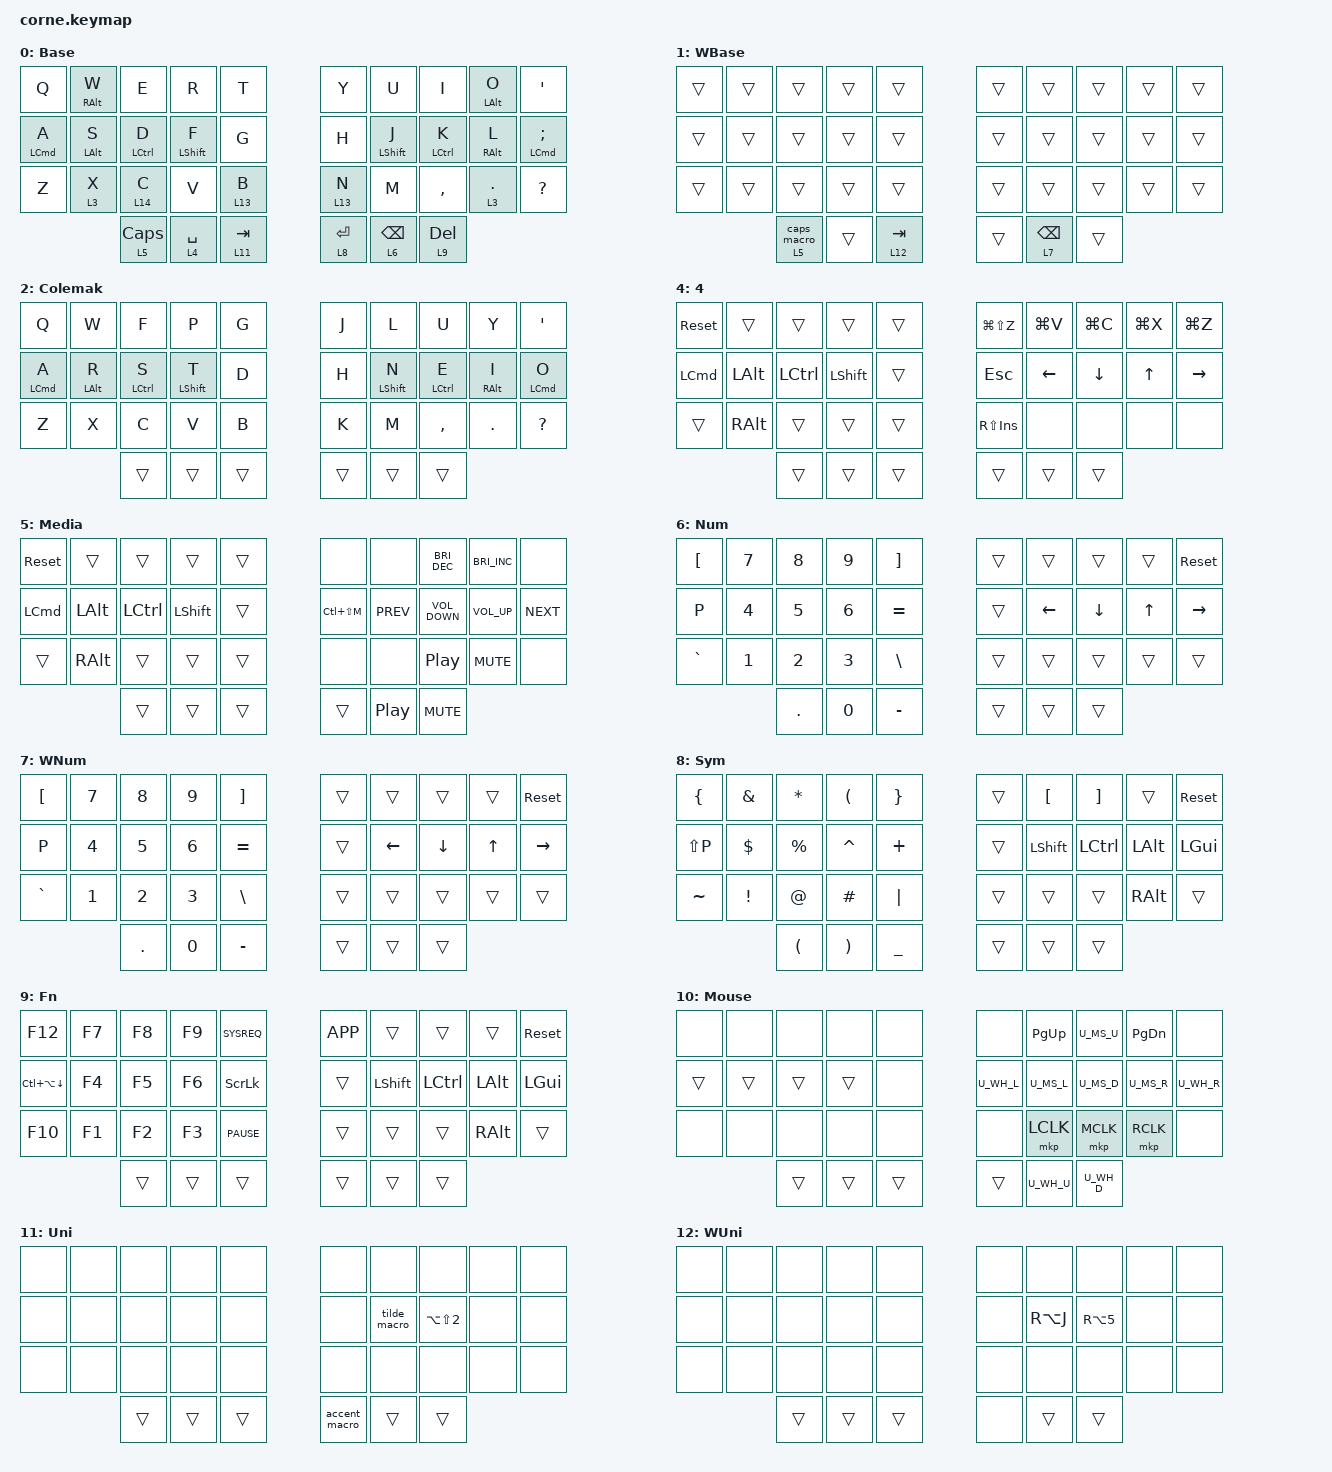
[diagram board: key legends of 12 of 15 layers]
/*
 * Copyright (c) 2020 The ZMK Contributors
 *
 * SPDX-License-Identifier: MIT
 */

#include <behaviors.dtsi>
#include <dt-bindings/zmk/bt.h>
#include <dt-bindings/zmk/keys.h>
#include <dt-bindings/zmk/pointing.h>
#include "mouse.dtsi"

//#include "zmk-helpers/helper.h"
//#include "zmk-helpers/key-labels/36.h"

#define COMBO_IDLE_MS 280
#define MOUSE 10

// Smart-mouse, requires tri-state module.
/*
ZMK_TRI_STATE(
    smart_mouse,
    bindings = <&tog MOUSE>, <&none>, <&tog MOUSE>;
    ignored-key-positions =
        <RT0 RT1 RT2 RT3 RM0 RM1 RM2 RM3 RM4 RB1 RB2 RB3 RH1 RH2>;
    ignored-layers = <MOUSE>;
)
*/

&caps_word { continue-list = <UNDERSCORE BACKSPACE DELETE SEMICOLON>; };

/ {
    chosen { zmk,matrix_transform = &five_column_transform; };
};

/ {
    behaviors {
        smart_mouse: smart_mouse {
            compatible = "zmk,behavior-tri-state";
            label = "SMART_MOUSE";
            #binding-cells = <0>;

            /* first press, second press, interruption */

            bindings = <&tog MOUSE>, <&none>, <&tog MOUSE>;

            /* optional: start simple, add these later if desired */

            ignored-key-positions = <5 6 7 8 9 10 11 12 13 14 15 16 17 18 19 25 26 27 28 29 33 34 35>;
            ignored-layers = <MOUSE>;
        };

        hold_layer: hold_layer {
            compatible = "zmk,behavior-hold-tap";
            label = "HOLD_LAYER";
            bindings = <&mo>, <&kp>;

            #binding-cells = <2>;
            tapping-term-ms = <175>;
            flavor = "tap-preferred";
            quick-tap-ms = <250>;
        };

        hold_tap: hold_tap {
            compatible = "zmk,behavior-hold-tap";
            label = "HOLD_TAP";
            bindings = <&kp>, <&kp>;

            #binding-cells = <2>;
            tapping-term-ms = <250>;
            flavor = "tap-preferred";
        };

        hmr: hmr {
            compatible = "zmk,behavior-hold-tap";
            label = "HMR";
            bindings = <&kp>, <&kp>;

            #binding-cells = <2>;
            tapping-term-ms = <230>;
            quick-tap-ms = <175>;
            require-prior-idle-ms = <150>;
            flavor = "balanced";
            hold-trigger-key-positions = <0 1 2 3 4 10 11 12 13 14 20 21 22 23 24 30 31 32 33 34 35>;
            hold-trigger-on-release;
        };

        hml: hml {
            compatible = "zmk,behavior-hold-tap";
            label = "HML";
            bindings = <&kp>, <&kp>;

            #binding-cells = <2>;
            tapping-term-ms = <230>;
            quick-tap-ms = <175>;
            require-prior-idle-ms = <150>;
            flavor = "balanced";
            hold-trigger-on-release;
            hold-trigger-key-positions = <5 6 7 8 9 15 16 17 18 19 25 26 27 28 29 33 34 35 30 31 32>;
        };

        lpar_lt: lpar_lt {
            compatible = "zmk,behavior-mod-morph";
            label = "LPAR_LT";
            bindings = <&kp LPAR>, <&kp LT>;

            #binding-cells = <0>;
            mods = <(MOD_LSFT)>;
        };

        hmr_parens_lt: hmr_parens_lt {
            compatible = "zmk,behavior-hold-tap";
            label = "HMR_PARENS_LT";
            bindings = <&kp>, <&parens_lt>;

            #binding-cells = <2>;
            tapping-term-ms = <280>;
            quick-tap-ms = <175>;
            require-prior-idle-ms = <150>;
            flavor = "balanced";
            hold-trigger-key-positions = <0 1 2 3 4 10 11 12 13 14 20 21 22 23 24 30 31 32 33 34 35>;
            hold-trigger-on-release;
        };

        rpar_gt: rpar_gt {
            compatible = "zmk,behavior-mod-morph";
            label = "RPAR_GT";
            bindings = <&kp RPAR>, <&kp GT>;

            #binding-cells = <0>;
            mods = <(MOD_LSFT)>;
        };

        hmr_curlybkts_gt: hmr_curlybkts_gt {
            compatible = "zmk,behavior-hold-tap";
            label = "HMR_CURLYBKTS_GT";
            bindings = <&kp>, <&curlybkts_gt>;

            #binding-cells = <2>;
            tapping-term-ms = <280>;
            quick-tap-ms = <175>;
            require-prior-idle-ms = <150>;
            flavor = "balanced";
            hold-trigger-key-positions = <0 1 2 3 4 10 11 12 13 14 20 21 22 23 24 30 31 32 33 34 35>;
            hold-trigger-on-release;
        };

        lbkt_lbrc: lbkt_lbrc {
            compatible = "zmk,behavior-mod-morph";
            label = "LBKT_LBRC";
            bindings = <&kp LBKT>, <&kp LBRC>;

            #binding-cells = <0>;
            mods = <(MOD_LSFT)>;
        };

        rbkt_rbrc: rbkt_rbrc {
            compatible = "zmk,behavior-mod-morph";
            label = "RBKT_RBRC";
            bindings = <&kp RBKT>, <&kp RBRC>;

            #binding-cells = <0>;
            mods = <(MOD_LSFT)>;
        };

        hml_repeat: hml_repeat {
            compatible = "zmk,behavior-hold-tap";
            label = "HML_REPEAT";
            bindings = <&kp>, <&key_repeat>;

            #binding-cells = <2>;
            tapping-term-ms = <280>;
            quick-tap-ms = <175>;
            require-prior-idle-ms = <150>;
            flavor = "balanced";
            hold-trigger-on-release;
            hold-trigger-key-positions = <5 6 7 8 9 15 16 17 18 19 25 26 27 28 29 33 34 35 32 31 30>;
        };

        holdLayer_Caps: holdLayer_Caps {
            compatible = "zmk,behavior-hold-tap";
            label = "HOLDLAYER_CAPS";
            bindings = <&mo>, <&caps_macro>;

            #binding-cells = <2>;
            tapping-term-ms = <175>;
            quick-tap-ms = <250>;
            flavor = "tap-preferred";
        };

        parens_lt: parens_lt {
            compatible = "zmk,behavior-mod-morph";
            label = "PARENS_LT";
            bindings = <&parens_macro>, <&kp LESS_THAN>;

            #binding-cells = <0>;
            mods = <(MOD_LSFT)>;
        };

        curlybkts_gt: curlybkts_gt {
            compatible = "zmk,behavior-mod-morph";
            label = "CURLYBKTS_GT";
            bindings = <&curlybkts_macro>, <&kp GT>;

            #binding-cells = <0>;
            mods = <(MOD_LSFT)>;
        };

        sqbkts_none: sqbkts_none {
            compatible = "zmk,behavior-mod-morph";
            label = "SQBKTS_NONE";
            bindings = <&sqbkts_macro>, <&none>;

            #binding-cells = <0>;
            mods = <(MOD_LSFT)>;
        };

        hmr_shft: hmr_shft {
            compatible = "zmk,behavior-hold-tap";
            label = "HMR_SHFT";
            bindings = <&kp>, <&kp>;

            #binding-cells = <2>;
            tapping-term-ms = <280>;
            quick-tap-ms = <175>;
            require-prior-idle-ms = <150>;
            flavor = "balanced";
            hold-trigger-on-release;
            hold-trigger-key-positions = <0 1 3 4 10 11 20 21 22 23 24 30 31 32 0 1 2 3 4 10 11 20 21 22 23 24 30 31 32 12 13 14>;
        };

        hml_shft: hml_shft {
            compatible = "zmk,behavior-hold-tap";
            label = "HML_SHFT";
            bindings = <&kp>, <&kp>;

            #binding-cells = <2>;
            tapping-term-ms = <280>;
            quick-tap-ms = <175>;
            require-prior-idle-ms = <150>;
            flavor = "balanced";
            hold-trigger-on-release;
            hold-trigger-key-positions = <5 6 7 8 9 15 18 19 25 26 27 28 29 33 34 35 16 17>;
        };

        sl_hold_tap: sl_hold_tap {
            compatible = "zmk,behavior-hold-tap";
            label = "SL_HOLD_TAP";
            bindings = <&sl>, <&kp>;

            #binding-cells = <2>;
            tapping-term-ms = <200>;
            flavor = "tap-preferred";
        };

        quote_dblquote: quote_dblquote {
            compatible = "zmk,behavior-mod-morph";
            label = "QUOTE_DBLQUOTE";
            bindings = <&dblquote_macro>, <&quote_macro>;

            #binding-cells = <0>;
            mods = <(MOD_LSFT)>;
        };

        dbckwrd_dbckline: dbckwrd_dbckline {
            compatible = "zmk,behavior-mod-morph";
            label = "DBCKWRD_DBCKLINE";
            bindings = <&kp LA(BACKSPACE)>, <&kp RG(BACKSPACE)>;

            #binding-cells = <0>;
            mods = <(MOD_LSFT)>;
        };

        win_dbckwrd_dbckline: win_dbckwrd_dbckline {
            compatible = "zmk,behavior-mod-morph";
            label = "WIN_DBCKWRD_DBCKLINE";
            bindings = <&kp LC(BACKSPACE)>, <&win_dbckline_macro>;

            #binding-cells = <0>;
            mods = <(MOD_LSFT)>;
        };

        dfwdwrd_dfwdline: dfwdwrd_dfwdline {
            compatible = "zmk,behavior-mod-morph";
            label = "DFWDWRD_DFWDLINE";
            bindings = <&kp LA(DEL)>, <&dfwdline_macro>;

            #binding-cells = <0>;
            mods = <(MOD_LSFT)>;
        };

        win_dfwdwrd_dfwdline: win_dfwdwrd_dfwdline {
            compatible = "zmk,behavior-mod-morph";
            label = "WIN_DFWDWRD_DFWDLINE";
            bindings = <&kp LC(DEL)>, <&win_dfwdline_macro>;

            #binding-cells = <0>;
            mods = <(MOD_LSFT)>;
        };

        sqk: sqk {
            compatible = "zmk,behavior-sticky-key";
            label = "SQK";
            bindings = <&kp>;
            #binding-cells = <1>;
            quick-release;
            ignore-modifiers;
            release-after-ms = <60000>;
        };

        td_tmux: tap_dance_tmux {
            compatible = "zmk,behavior-tap-dance";
            label = "TAP_DANCE_TMUX";
            #binding-cells = <0>;
            tapping-term-ms = <200>;
            bindings = <&kp LC(A)>, <&kp LC(G)>;
        };

        fn_ptt: fn_ptt {
            compatible = "zmk,behavior-hold-tap";
            label = "FN_PTT";
            bindings = <&kp>, <&kp>;

            #binding-cells = <2>;
            tapping-term-ms = <170>;
            flavor = "tap-preferred";
        };
    };

    combos {
        compatible = "zmk,combos";

        mac_layer {
            bindings = <&to 0>;
            key-positions = <23 26>;
            layers = <13 2 3 4 5 6 8 9 10 1 7>;
        };

        lower_layer {
            bindings = <&to 13>;
            key-positions = <23 26>;
            layers = <0>;
            timeout-ms = <25>;
        };

        num_layer {
            bindings = <&to 6>;
            key-positions = <3 4>;
            layers = <0>;
        };

        caps_word {
            bindings = <&caps_word>;
            key-positions = <14 15>;
        };

        lock_screen {
            bindings = <&kp LC(LG(Q))>;
            key-positions = <0 9>;
        };

        cut {
            bindings = <&kp LG(X)>;
            key-positions = <23 21>;
            layers = <0 6>;
        };

        copy {
            bindings = <&kp LG(C)>;
            key-positions = <21 22>;
            layers = <0 6>;
        };

        paste {
            bindings = <&kp LG(V)>;
            key-positions = <22 23>;
            layers = <0 6>;
        };

        parens_lt {
            bindings = <&hmr_parens_lt RS(LCTRL) 0>;
            key-positions = <16 17>;
            require-prior-idle-ms = <COMBO_IDLE_MS>;
        };

        curlybkts_gt {
            bindings = <&hmr_curlybkts_gt RS(LALT) 0>;
            key-positions = <17 18>;
            require-prior-idle-ms = <COMBO_IDLE_MS>;
        };

        sqbkts_none {
            bindings = <&sqbkts_none>;
            key-positions = <26 27>;
            require-prior-idle-ms = <COMBO_IDLE_MS>;
        };

        none {
            bindings = <&none>;
            key-positions = <27 28>;
        };

        caret {
            bindings = <&kp CARET>;
            key-positions = <5 15>;
        };

        plus {
            bindings = <&kp PLUS>;
            key-positions = <6 16>;
        };

        star {
            bindings = <&kp STAR>;
            key-positions = <7 17>;
        };

        amps {
            bindings = <&kp AMPS>;
            key-positions = <8 18>;
        };

        under {
            bindings = <&kp UNDER>;
            key-positions = <15 25>;
        };

        minus {
            bindings = <&kp MINUS>;
            key-positions = <26 16>;
        };

        fslh {
            bindings = <&kp FSLH>;
            key-positions = <17 27>;
        };

        pipe {
            bindings = <&kp PIPE>;
            key-positions = <18 28>;
        };

        backspace {
            bindings = <&kp BACKSPACE>;
            key-positions = <1 2>;
        };

        enter {
            bindings = <&kp ENTER>;
            key-positions = <2 3>;
        };

        tab {
            bindings = <&hml LS(LALT) TAB>;
            key-positions = <11 12>;
        };

        repeat {
            bindings = <&hml_repeat LS(LCTRL) 0>;
            key-positions = <12 13>;
        };

        space {
            bindings = <&kp SPACE>;
            key-positions = <14 13>;
        };

        cut_win {
            bindings = <&kp LC(X)>;
            key-positions = <23 21>;
            layers = <1 7>;
        };

        copy_win {
            bindings = <&kp LC(INS)>;
            key-positions = <21 22>;
            layers = <1 7>;
        };

        paste_win {
            bindings = <&kp LS(INS)>;
            key-positions = <23 22>;
            layers = <1 7>;
        };

        at {
            bindings = <&kp AT>;
            key-positions = <1 11>;
        };

        hash {
            bindings = <&kp HASH>;
            key-positions = <2 12>;
        };

        dllr {
            bindings = <&kp DLLR>;
            key-positions = <3 13>;
        };

        prcnt {
            bindings = <&kp PRCNT>;
            key-positions = <4 14>;
        };

        grave {
            bindings = <&kp GRAVE>;
            key-positions = <11 21>;
        };

        bslh {
            bindings = <&kp BSLH>;
            key-positions = <12 22>;
        };

        equal {
            bindings = <&kp EQUAL>;
            key-positions = <13 23>;
        };

        tilde {
            bindings = <&kp TILDE>;
            key-positions = <14 24>;
        };

        tmux_leading {
            bindings = <&td_tmux>;
            key-positions = <34 31>;
        };

        fn_ptt {
            bindings = <&fn_ptt F16 LC(F16)>;
            key-positions = <31 32>;
        };

        R_in_pipe {
            bindings = <&R_in_pipe>;
            key-positions = <16 18>;
            require-prior-idle-ms = <COMBO_IDLE_MS>;
        };

        R_pipe {
            bindings = <&R_pipe>;
            key-positions = <3 16>;
            require-prior-idle-ms = <COMBO_IDLE_MS>;
        };

        mouse {
            bindings = <&smart_mouse>;
            key-positions = <5 6>;
        };

        caps {
            bindings = <&kp ESC>;
            key-positions = <15 16>;
            layers = <0 2>;
        };

        win_layer {
            bindings = <&to 1>;
            key-positions = <24 25>;
            layers = <13 2 3 4 5 8 9 10 0 7 6>;
        };

        caps_win {
            bindings = <&kp ESC>;
            key-positions = <15 16>;
            layers = <1>;
        };

        start_line {
            bindings = <&kp LG(LEFT)>;
            key-positions = <25 26>;
            layers = <0>;
        };

        end_line {
            bindings = <&kp LG(RIGHT)>;
            key-positions = <29 28>;
            layers = <0>;
        };

        start_line_win {
            bindings = <&kp HOME>;
            key-positions = <25 26>;
            layers = <1>;
        };

        end_line_win {
            bindings = <&kp END>;
            key-positions = <29 28>;
            layers = <1>;
        };

        mac_scrnsht {
            bindings = <&kp LG(LC(LS(NUMBER_4)))>;
            key-positions = <20 21>;
            layers = <0>;
        };

        win_scrnsht {
            bindings = <&kp PSCRN>;
            key-positions = <20 21>;
            layers = <1>;
        };

        dbck_wrd {
            bindings = <&kp LA(BACKSPACE)>;
            key-positions = <>;
            layers = <0>;
        };

        dnxt_wrd {
            bindings = <&kp LA(DEL)>;
            key-positions = <>;
            layers = <0>;
        };

        win_dbck_wrd {
            bindings = <&kp LC(BACKSPACE)>;
            key-positions = <>;
            layers = <1>;
        };

        win_dnxt_wrd {
            bindings = <&kp LC(DEL)>;
            key-positions = <>;
            layers = <1>;
        };

        navbck_wrd {
            bindings = <&kp LA(LEFT)>;
            key-positions = <6 7>;
            layers = <0>;
        };

        navnxt_wrd {
            bindings = <&kp LA(RIGHT)>;
            key-positions = <7 8>;
            layers = <0>;
        };

        win_navbck_wrd {
            bindings = <&kp LC(LEFT)>;
            key-positions = <6 7>;
            layers = <1>;
        };

        win_navnxt_wrd {
            bindings = <&kp LC(RIGHT)>;
            key-positions = <7 8>;
            layers = <1>;
        };

        clipboard {
            bindings = <&kp RA(RG(C))>;
            key-positions = <10 11>;
            layers = <0>;
            require-prior-idle-ms = <COMBO_IDLE_MS>;
        };

        win_clipboard {
            bindings = <&kp LC(GRAVE)>;
            key-positions = <10 11>;
            layers = <1>;
            require-prior-idle-ms = <COMBO_IDLE_MS>;
        };

        wnum_layer {
            bindings = <&to 7>;
            key-positions = <3 4>;
            layers = <1>;
        };

        quote_dblquote {
            bindings = <&quote_dblquote>;
            key-positions = <9 19>;
            require-prior-idle-ms = <COMBO_IDLE_MS>;
        };

        dbckwrd_dbckline {
            bindings = <&dbckwrd_dbckline>;
            key-positions = <30 31>;
            layers = <0>;
        };

        win_dbckwrd_dbckline {
            bindings = <&win_dbckwrd_dbckline>;
            key-positions = <30 31>;
            layers = <1>;
        };

        dfwdwrd_dfwdline {
            bindings = <&dfwdwrd_dfwdline>;
            key-positions = <35 34>;
            layers = <0>;
        };

        win_dfwdwrd_dfwdline {
            bindings = <&win_dfwdwrd_dfwdline>;
            key-positions = <35 34>;
            layers = <1>;
        };

        shift-enter {
            bindings = <&kp RS(ENTER)>;
            key-positions = <16 33>;
        };

        sticky-shift {
            bindings = <&sqk LEFT_SHIFT>;
            key-positions = <32 33>;
        };

        win_context_menu {
            bindings = <&kp K_CONTEXT_MENU>;
            key-positions = <0 1>;
        };
    };

    macros {
        R_in_pipe: R_in_pipe {
            compatible = "zmk,behavior-macro";
            #binding-cells = <0>;
            bindings = <&none &kp PRCNT &kp L &kp J &kp PRCNT>;
            label = "R_IN_PIPE";
        };

        R_pipe: R_pipe {
            compatible = "zmk,behavior-macro";
            #binding-cells = <0>;
            bindings = <&none &kp PRCNT &kp GT &kp PRCNT>;
            label = "R_PIPE";
        };

        caps_macro: caps_macro {
            compatible = "zmk,behavior-macro";
            #binding-cells = <0>;
            bindings = <&kp CAPS>;
            label = "CAPS_MACRO";
            tap-ms = <200>;
        };

        parens_macro: macro_parens {
            compatible = "zmk,behavior-macro";
            #binding-cells = <0>;
            bindings = <&kp LPAR &kp RPAR &kp LEFT>;
            label = "MACRO_PARENS";
        };

        sqbkts_macro: sqbkts_macro {
            compatible = "zmk,behavior-macro";
            #binding-cells = <0>;
            bindings = <&kp LBKT &kp RBKT &kp LEFT>;
            label = "SQBKTS_MACRO";
        };

        curlybkts_macro: curlybkts_macro {
            compatible = "zmk,behavior-macro";
            #binding-cells = <0>;
            bindings = <&kp LEFT_BRACE &kp RIGHT_BRACE &kp LEFT>;
            label = "CURLYBKTS_MACRO";
        };

        tilde_macro: enye_macro {
            compatible = "zmk,behavior-macro";
            #binding-cells = <0>;
            bindings =
                <&macro_press>,
                <&kp LEFT_ALT>,
                <&macro_tap>,
                <&kp J>,
                <&macro_release>,
                <&kp LEFT_ALT>;

            label = "ENYE_MACRO";
        };

        accent_macro: accent_macro {
            compatible = "zmk,behavior-macro";
            #binding-cells = <0>;
            bindings =
                <&macro_press>,
                <&kp LEFT_ALT>,
                <&macro_tap>,
                <&kp K>,
                <&macro_release>,
                <&kp LEFT_ALT>;

            label = "ACCENT_MACRO";
        };

        euro_macro: euro_macro {
            compatible = "zmk,behavior-macro";
            #binding-cells = <0>;
            bindings =
                <&macro_press>,
                <&kp LEFT_ALT &kp LEFT_SHIFT>,
                <&macro_tap>,
                <&kp NUMBER_2>,
                <&macro_release>,
                <&kp LEFT_ALT &kp LEFT_SHIFT>;

            label = "EURO_MACRO";
        };

        quote_macro: quote_macro {
            compatible = "zmk,behavior-macro";
            #binding-cells = <0>;
            bindings = <&kp SQT &kp SQT &kp LEFT>;
            label = "QUOTE_MACRO";
        };

        dblquote_macro: dblquote_macro {
            compatible = "zmk,behavior-macro";
            #binding-cells = <0>;
            bindings = <&kp DOUBLE_QUOTES &kp DOUBLE_QUOTES &kp LEFT>;
            label = "DBLQUOTE_MACRO";
        };

        win_dbckline_macro: win_dbckline_macro {
            compatible = "zmk,behavior-macro";
            #binding-cells = <0>;
            bindings = <&kp RS(HOME) &kp BACKSPACE>;
            label = "WIN_DBCKLINE_MACRO";
        };

        dfwdline_macro: dfwdline_macro {
            compatible = "zmk,behavior-macro";
            #binding-cells = <0>;
            bindings = <&kp LS(LG(RIGHT)) &kp BACKSPACE>;
            label = "DFWDLINE_MACRO";
        };

        win_dfwdline_macro: win_dfwdline_macro {
            compatible = "zmk,behavior-macro";
            #binding-cells = <0>;
            bindings = <&kp RS(END) &kp BACKSPACE>;
            label = "WIN_DFWDLINE_MACRO";
        };

        // Opens Moom keyboard control (Ctrl+Shift+M), then sends the preset digit.
        moom: moom {
            compatible = "zmk,behavior-macro-one-param";
            #binding-cells = <1>;
            bindings =
                <&macro_wait_time 120>,
                <&macro_tap &kp LS(LC(M))>,
                <&macro_param_1to1>,
                <&macro_tap &kp MACRO_PLACEHOLDER>;

            label = "MOOM";
        };
    };

    keymap {
        compatible = "zmk,keymap";

        mac_layer {
            // -----------------------------------------------------------------------------------------
            // |  TAB |  Q  |  W  |  E  |  R  |  T  |   |  Y  |  U   |  I  |  O  |  P  | BKSP |
            // | CTRL |  A  |  S  |  D  |  F  |  G  |   |  H  |  J   |  K  |  L  |  ;  |  '   |
            // | SHFT |  Z  |  X  |  C  |  V  |  B  |   |  N  |  M   |  ,  |  .  |  /  | ESC  |
            //                    | GUI | LWR | SPC |   | ENT | RSE  | ALT |

            label = "Base";
            bindings = <
  &kp Q        &hml RALT W      &kp E               &kp R                   &kp T                 &kp Y                &kp U                    &kp I              &hmr LALT O        &kp SQT
  &hml LCMD A  &hml LALT S      &hml LCTRL D        &hml_shft LEFT_SHIFT F  &kp G                 &kp H                &hmr_shft LEFT_SHIFT J   &hmr LCTRL K       &hmr RALT L        &hmr LCMD SEMI
  &kp Z        &hold_layer 3 X  &hold_layer 14 C    &kp V                  &hold_layer 13 B      &hold_layer 13 N     &kp M                    &kp COMMA          &hold_layer 3 DOT  &kp QUESTION
                                &hold_layer 5 CAPS  &hold_layer 4 SPACE     &hold_layer 11 TAB    &hold_layer 8 ENTER  &hold_layer 6 BACKSPACE  &hold_layer 9 DEL
            >;
        };

        win_layer {
            label = "WBase";
            bindings = <
  &trans  &trans  &trans               &trans  &trans                &trans  &trans                   &trans  &trans  &trans
  &trans  &trans  &trans               &trans  &trans                &trans  &trans                   &trans  &trans  &trans
  &trans  &trans  &trans               &trans  &trans                &trans  &trans                   &trans  &trans  &trans
                  &holdLayer_Caps 5 0  &trans  &hold_layer 12 TAB    &trans  &hold_layer 7 BACKSPACE  &trans
            >;
        };

        colemak_kb {
            // -----------------------------------------------------------------------------------------
            // |  TAB |  !  |  @  |  #  |  $  |  %  |   |  ^  |  &  |  *  |  (  |  )  | BKSP |
            // | CTRL |     |     |     |     |     |   |  -  |  =  |  [  |  ]  |  \  |  `   |
            // | SHFT |     |     |     |     |     |   |  _  |  +  |  {  |  }  | "|" |  ~   |
            //                    | GUI |     | SPC |   | ENT |     | ALT |

            label = "Colemak";
            bindings = <
  &kp Q        &kp W        &kp F         &kp P              &kp G     &kp J   &kp L              &kp U         &kp Y        &kp SQT
  &hml LCMD A  &hml LALT R  &hml LCTRL S  &hml LEFT_SHIFT T  &kp D     &kp H   &hmr LEFT_SHIFT N  &hmr LCTRL E  &hmr RALT I  &hmr LCMD O
  &kp Z        &kp X        &kp C         &kp V              &kp B     &kp K   &kp M              &kp COMMA     &kp DOT      &kp QUESTION
                            &trans        &trans             &trans    &trans  &trans             &trans
            >;
        };

        layer_3 {
            label = "Shortcuts";
            bindings = <
  &none  &none  &kp LG(LC(LS(E)))  &none              &kp LG(LC(LS(T)))    &none   &none              &none              &kp LG(LC(LS(O)))  &none
  &none  &none  &kp LG(LC(LS(D)))  &kp LG(LC(LS(F)))  &none                &none   &kp LG(LC(LS(J)))  &kp LG(LC(LS(K)))  &none              &none
  &none  &none  &kp LG(LC(LS(C)))  &none              &none                &none   &kp LG(LC(LS(M)))  &none              &none              &none
                &trans             &trans             &trans               &trans  &trans             &trans
            >;
        };

        layer_4 {
            label = "4";
            bindings = <
  &sys_reset  &trans         &trans     &trans          &trans    &kp LG(LS(Z))  &kp LG(V)  &kp LG(C)  &kp LG(X)  &kp LG(Z)
  &kp LCMD    &kp LEFT_ALT   &kp LCTRL  &kp LEFT_SHIFT  &trans    &kp ESC        &kp LEFT   &kp DOWN   &kp UP     &kp RIGHT
  &trans      &kp RIGHT_ALT  &trans     &trans          &trans    &kp RS(INS)    &none      &none      &none      &none
                             &trans     &trans          &trans    &trans         &trans     &trans
            >;
        };

        layer_6 {
            label = "Media";
            bindings = <
  &sys_reset  &trans         &trans     &trans          &trans    &none          &none       &kp C_BRIGHTNESS_DEC  &kp C_BRIGHTNESS_INC  &none
  &kp LCMD    &kp LEFT_ALT   &kp LCTRL  &kp LEFT_SHIFT  &trans    &kp LC(LS(M))  &kp C_PREV  &kp C_VOLUME_DOWN     &kp C_VOL_UP          &kp C_NEXT
  &trans      &kp RIGHT_ALT  &trans     &trans          &trans    &none          &none       &kp C_PP              &kp C_MUTE            &none
                             &trans     &trans          &trans    &trans         &kp C_PP    &kp C_MUTE
            >;
        };

        mac_num {
            label = "Num";
            bindings = <
  &kp LBKT   &kp N7  &kp N8   &kp N9  &kp RBKT     &trans  &trans    &trans    &trans  &sys_reset
  &kp P      &kp N4  &kp N5   &kp N6  &kp EQUAL    &trans  &kp LEFT  &kp DOWN  &kp UP  &kp RIGHT
  &kp GRAVE  &kp N1  &kp N2   &kp N3  &kp BSLH     &trans  &trans    &trans    &trans  &trans
                     &kp DOT  &kp N0  &kp MINUS    &trans  &trans    &trans
            >;
        };

        win_num {
            label = "WNum";
            bindings = <
  &kp LBKT   &kp N7  &kp N8   &kp N9  &kp RBKT     &trans  &trans    &trans    &trans  &sys_reset
  &kp P      &kp N4  &kp N5   &kp N6  &kp EQUAL    &trans  &kp LEFT  &kp DOWN  &kp UP  &kp RIGHT
  &kp GRAVE  &kp N1  &kp N2   &kp N3  &kp BSLH     &trans  &trans    &trans    &trans  &trans
                     &kp DOT  &kp N0  &kp MINUS    &trans  &trans    &trans
            >;
        };

        layer_8 {
            label = "Sym";
            bindings = <
  &kp LEFT_BRACE  &kp AMPS    &kp STAR              &kp LEFT_PARENTHESIS   &kp RIGHT_BRACE    &trans  &kp LEFT_BRACKET  &kp RIGHT_BRACKET  &trans    &sys_reset
  &kp LS(P)       &kp DOLLAR  &kp PERCENT           &kp CARET              &kp PLUS           &trans  &kp LSHFT         &kp LCTRL          &kp LALT  &kp LGUI
  &kp TILDE       &kp EXCL    &kp AT                &kp HASH               &kp PIPE           &trans  &trans            &trans             &kp RALT  &trans
                              &kp LEFT_PARENTHESIS  &kp RIGHT_PARENTHESIS  &kp UNDER          &trans  &trans            &trans
            >;
        };

        layer_9 {
            label = "Fn";
            bindings = <
  &kp F12  &kp F7  &kp F8  &kp F9  &kp SYSREQ        &kp K_APP  &trans     &trans     &trans    &sys_reset
  &kp LC(LA(DOWN))  &kp F4  &kp F5  &kp F6  &kp SCROLLLOCK    &trans     &kp LSHFT  &kp LCTRL  &kp LALT  &kp LGUI
  &kp F10  &kp F1  &kp F2  &kp F3  &kp C_PAUSE       &trans     &trans     &trans     &kp RALT  &trans
                   &trans  &trans  &trans            &trans     &trans     &trans
            >;
        };

        layer_10 {
            label = "Mouse";
            bindings = <
  &none      &none      &none      &none                                     &none     &none   &kp PG_UP U_MS_U  &kp PG_DN             &none  &trans
  &trans     &trans     &trans     &none U_WH_L U_MS_L U_MS_D U_MS_R U_WH_R  &none     &none   &none             &none                 &none  &none
  &mkp LCLK  &mkp MCLK  &mkp RCLK  &none                                     &trans    &trans  &trans            &trans U_WH_U U_WH_D
            >;
        };

        unicode {
            label = "Uni";
            bindings = <
  &none  &none  &none   &none   &none     &none          &none         &none                 &none  &none
  &none  &none  &none   &none   &none     &none          &tilde_macro  &kp LA(LS(NUMBER_2))  &none  &none
  &none  &none  &none   &none   &none     &none          &none         &none                 &none  &none
                &trans  &trans  &trans    &accent_macro  &trans        &trans
            >;
        };

        win_unicode {
            label = "WUni";
            bindings = <
  &none  &none  &none   &none   &none     &none  &none      &none             &none  &none
  &none  &none  &none   &none   &none     &none  &kp RA(J)  &kp RA(NUMBER_5)  &none  &none
  &none  &none  &none   &none   &none     &none  &none      &none             &none  &none
                &trans  &trans  &trans    &none  &trans     &trans
            >;
        };

        config_layer {
            // -----------------------------------------------------------------------------------------
            // |  TAB |  1  |  2  |  3  |  4  |  5  |   |  6  |  7  |  8  |  9  |  0  | BKSP |
            // | BTCLR| BT1 | BT2 | BT3 | BT4 | BT5 |   | LFT | DWN |  UP | RGT |     |      |
            // | SHFT |     |     |     |     |     |   |     |     |     |     |     |      |
            //                    |BTCLR|     | SPC |   | ENT |     | ALT |

            label = "Config";
            bindings = <
  &kp N1        &kp N2        &kp N3         &kp N4        &kp N5          &kp N6  &kp N7  &kp N8  &kp N9  &kp N0
  &bt BT_SEL 0  &bt BT_SEL 1  &bt BT_SEL 2   &bt BT_SEL 3  &bt BT_SEL 4    &to 5   &to 6   &to 8   &to 9   &to 10
  &bt BT_CLR    &trans        &bt BT_DISC 2  &trans        &bootloader     &to 1   &to 2   &to 3   &to 4   &to 0
                              &trans         &trans        &trans          &trans  &trans  &trans
            >;
        };

        window_layer {
            // Hold C. Moom presets: 1/2/3 = left/center/right (resize), 4/5/6 = prev display/fill/next display, 0 = center.
            label = "Win";
            bindings = <
  &none  &none  &none   &none   &none     &none  &moom N4  &moom N5  &moom N6  &none
  &none  &none  &none   &none   &none     &none  &moom N1  &moom N2  &moom N3  &none
  &none  &none  &none   &none   &none     &none  &none     &moom N0  &none     &none
                &trans  &trans  &trans    &trans  &trans   &trans
            >;
        };
    };
};
